AUTOSAR XML (schema 00048)
package /HuaweiMDC/FunctionalSoftware/NavigationApplication/Execution
  executable NavigationExecutable
    root sw component prototype navigation: application-type=navigation
package /HuaweiMDC/FunctionalSoftware/NavigationApplication/SwComponent
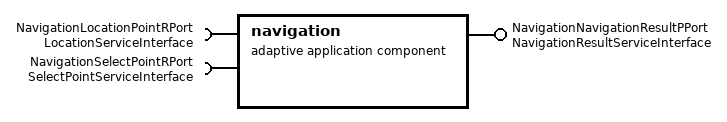
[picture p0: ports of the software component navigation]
  adaptive application sw component type navigation
    require port NavigationLocationPointRPort: required-interface=LocationServiceInterface
    provide port NavigationNavigationResultPPort: provided-interface=NavigationResultServiceInterface
    require port NavigationSelectPointRPort: required-interface=SelectPointServiceInterface
